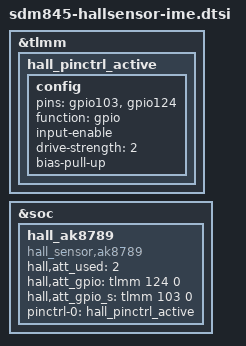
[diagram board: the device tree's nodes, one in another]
&tlmm {
	hall_pinctrl_active: hall_pinctrl_active {
		config {
			pins = "gpio103", "gpio124";
			function = "gpio";
			input-enable;
			drive-strength = <2>;
			bias-pull-up;
		};
	};
};

&soc {
        hall_ak8789 {
		compatible = "hall_sensor,ak8789";
		hall,att_used = <2>;
		hall,att_gpio = <&tlmm 124 0>;
		hall,att_gpio_s = <&tlmm 103 0>;
		pinctrl-names = "default";
		pinctrl-0 = <&hall_pinctrl_active>;
	};
};
